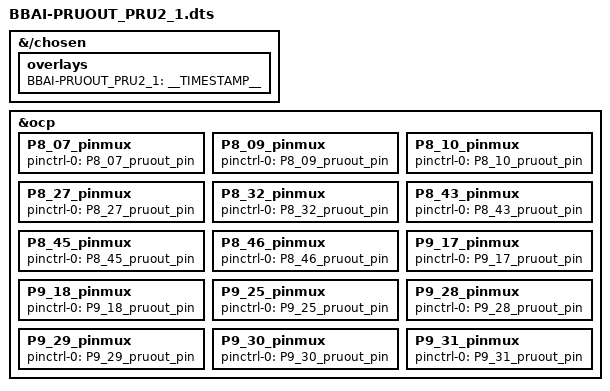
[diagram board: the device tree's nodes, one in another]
/*
 * Copyright (C) 2020 Deepak Khatri <deepaklorkhatri7@gmail.com>
 * See Cape Interface Spec page for more info on Bone Buses
 * https://elinux.org/Beagleboard:BeagleBone_cape_interface_spec
 *
 * Virtual cape for pr2_pru1_gpo* pins
 *
 * This program is free software; you can redistribute it and/or modify
 * it under the terms of the GNU General Public License version 2 as
 * published by the Free Software Foundation.
 */
/dts-v1/;
/plugin/;

/*
* Helper to show loaded overlays under: /proc/device-tree/chosen/overlays/
*/
&{/chosen} {
    overlays {
        BBAI-PRUOUT_PRU2_1 = __TIMESTAMP__;
    };
};

/*
 * Update the default pinmux of the pins.
 * See these files for the phandles (&P9_* & &P8_*)
 * BeagleBoard-DeviceTrees/v4.19.x-ti-overlays/src/arm/am335x-bone-common-univ.dtsi
 * BeagleBoard-DeviceTrees/v4.19.x-ti-overlays/src/arm/am572x-bone-common-univ.dtsi
 */
&ocp {
    P8_07_pinmux { pinctrl-0 = <&P8_07_pruout_pin>; }; /* pr2_pru1_gpo16 */
	P8_09_pinmux { pinctrl-0 = <&P8_09_pruout_pin>; }; /* pr2_pru1_gpo6 */
	P8_10_pinmux { pinctrl-0 = <&P8_10_pruout_pin>; }; /* pr2_pru1_gpo15 */
	P8_27_pinmux { pinctrl-0 = <&P8_27_pruout_pin>; }; /* pr2_pru1_gpo17 */
	P8_32_pinmux { pinctrl-0 = <&P8_32_pruout_pin>; }; /* pr2_pru1_gpo0 */
	P8_43_pinmux { pinctrl-0 = <&P8_43_pruout_pin>; }; /* pr2_pru1_gpo20 */
	P8_45_pinmux { pinctrl-0 = <&P8_45_pruout_pin>; }; /* pr2_pru1_gpo18 */
	P8_46_pinmux { pinctrl-0 = <&P8_46_pruout_pin>; }; /* pr2_pru1_gpo19 */

    P9_17_pinmux { pinctrl-0 = <&P9_17_pruout_pin>; }; /* pr2_pru1_gpo9 */
	P9_18_pinmux { pinctrl-0 = <&P9_18_pruout_pin>; }; /* pr2_pru1_gpo8 */
	P9_25_pinmux { pinctrl-0 = <&P9_25_pruout_pin>; }; /* pr2_pru1_gpo5 */
	P9_28_pinmux { pinctrl-0 = <&P9_28_pruout_pin>; }; /* pr2_pru1_gpo13 */
	P9_29_pinmux { pinctrl-0 = <&P9_29_pruout_pin>; }; /* pr2_pru1_gpo11 */
	P9_30_pinmux { pinctrl-0 = <&P9_30_pruout_pin>; }; /* pr2_pru1_gpo12 */
	P9_31_pinmux { pinctrl-0 = <&P9_31_pruout_pin>; }; /* pr2_pru1_gpo10 */
};
